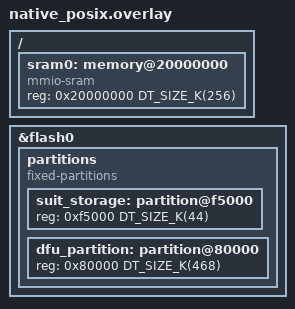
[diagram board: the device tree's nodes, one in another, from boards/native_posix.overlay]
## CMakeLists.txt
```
#
# Copyright (c) 2022 Nordic Semiconductor ASA
#
# SPDX-License-Identifier: LicenseRef-Nordic-5-Clause
#

cmake_minimum_required(VERSION 3.20.0)

find_package(Zephyr REQUIRED HINTS $ENV{ZEPHYR_BASE})

project(integration_test_envelope_decoder)
include(../cmake/test_template.cmake)

zephyr_library_link_libraries(suit_utils)
zephyr_library_link_libraries(suit_storage_interface)
zephyr_library_link_libraries(suit_execution_mode)
```

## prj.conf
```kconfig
#
# Copyright (c) 2022 Nordic Semiconductor ASA
#
# SPDX-License-Identifier: LicenseRef-Nordic-5-Clause
#

CONFIG_ZTEST=y

CONFIG_SUIT=y
CONFIG_SUIT_CRYPTO=y
CONFIG_SUIT_PROCESSOR=y
CONFIG_SUIT_PLATFORM=y
CONFIG_SUIT_LOG_LEVEL_DBG=y

CONFIG_SUIT_DEVCONFIG=y
CONFIG_SUIT_STORAGE=y
CONFIG_SUIT_MCI=y
CONFIG_SUIT_MCI_IMPL_CUSTOM=y
CONFIG_SUIT_METADATA=y
CONFIG_SUIT_PLAT_CHECK_COMPONENT_COMPATIBILITY=y
CONFIG_SUIT_PLAT_CHECK_CLASSES=y
CONFIG_SUIT_AUTHENTICATE=y

CONFIG_SUIT_CACHE=y
CONFIG_SUIT_DIGEST=y
CONFIG_SUIT_DIGEST_CACHE=y
CONFIG_SUIT_SINK_SELECTOR=y

CONFIG_SUIT_STREAM=y
CONFIG_SUIT_STREAM_SINK_DIGEST=y
CONFIG_SUIT_CHECK_IMAGE_MATCH=y

CONFIG_SUIT_STREAM_SINK_MEMPTR=y
CONFIG_SUIT_STREAM_SINK_FLASH=y
CONFIG_SUIT_STREAM_SOURCE_MEMPTR=y
CONFIG_SUIT_STREAM_SOURCE_CACHE=y

CONFIG_SUIT_UTILS=y
CONFIG_SUIT_MEMPTR_STORAGE=y

CONFIG_PSA_WANT_ALG_ECDSA=y

CONFIG_ZCBOR=y
CONFIG_ZCBOR_CANONICAL=y

CONFIG_FLASH=y
CONFIG_FLASH_MAP=y

CONFIG_SUIT_EXECUTION_MODE=y
```

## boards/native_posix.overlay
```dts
/*
 * Copyright (c) 2022 Nordic Semiconductor ASA
 *
 * SPDX-License-Identifier: LicenseRef-Nordic-5-Clause
 */

&flash0 {
	partitions {
		compatible = "fixed-partitions";
		#address-cells = <1>;
		#size-cells = <1>;

		/* Use the last 44KB of NVM as suit storage. */
		suit_storage: partition@f5000 {
			reg = <0xf5000 DT_SIZE_K(44)>;
		};

		/* Use the second half of NVM as DFU partition. */
		dfu_partition: partition@80000 {
			reg = <0x80000 DT_SIZE_K(468)>;
		};
	};
};

/ {
	sram0: memory@20000000 {
		compatible = "mmio-sram";
		reg = <0x20000000 DT_SIZE_K(256)>;
	};
};
```

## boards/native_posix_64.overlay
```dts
/*
 * Copyright (c) 2022 Nordic Semiconductor ASA
 *
 * SPDX-License-Identifier: LicenseRef-Nordic-5-Clause
 */

&flash0 {
	partitions {
		compatible = "fixed-partitions";
		#address-cells = <1>;
		#size-cells = <1>;

		/* Use the last 40KB of NVM as suit storage. */
		suit_storage: partition@f6000 {
			reg = <0xf6000 DT_SIZE_K(40)>;
		};

		/* Use the second half of NVM as DFU partition. */
		dfu_partition: partition@80000 {
			reg = <0x80000 DT_SIZE_K(472)>;
		};
	};
};

/ {
	sram0: memory@20000000 {
		compatible = "mmio-sram";
		reg = <0x20000000 DT_SIZE_K(256)>;
	};
};
```

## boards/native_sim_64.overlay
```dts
/*
 * Copyright (c) 2022 Nordic Semiconductor ASA
 *
 * SPDX-License-Identifier: LicenseRef-Nordic-5-Clause
 */

&flash0 {
	partitions {
		compatible = "fixed-partitions";
		#address-cells = <1>;
		#size-cells = <1>;

		/* Use the last 48KB of NVM as suit storage. */
		suit_storage: partition@f4000 {
			reg = <0xf4000 DT_SIZE_K(48)>;
		};

		/* Use the second half of NVM as DFU partition. */
		dfu_partition: partition@80000 {
			reg = <0x80000 DT_SIZE_K(468)>;
		};
	};
};

/ {
	sram0: memory@20000000 {
		compatible = "mmio-sram";
		reg = <0x20000000 DT_SIZE_K(256)>;
	};
};
```

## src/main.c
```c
/*
 * Copyright (c) 2022 Nordic Semiconductor ASA
 *
 * SPDX-License-Identifier: LicenseRef-Nordic-5-Clause
 */

#include <zephyr/ztest.h>
#include <stdint.h>
#include <zephyr/drivers/flash.h>
#include <zephyr/storage/flash_map.h>
#include <suit_plat_mem_util.h>

#include <suit.h>
#include <suit_platform.h>
#include <suit_mci.h>
#include <suit_storage.h>

#define DFU_PARTITION_ADDRESS (suit_plat_mem_nvm_ptr_get(DFU_PARTITION_OFFSET))
#define DFU_PARTITION_OFFSET  ((size_t)FIXED_PARTITION_OFFSET(dfu_partition))
#define DFU_PARTITION_SIZE    ((size_t)FIXED_PARTITION_SIZE(dfu_partition))

static void *test_suit_setup(void)
{
	int err = suit_storage_init();

	zassert_equal(err, 0, "Unable to initialize storage module");

	err = suit_mci_init();
	zassert_equal(err, 0, "Unable to initialize MCI module");

	err = suit_processor_init();
	zassert_equal(err, 0, "Unable to initialise SUIT processor (err: %d)", err);

	return NULL;
}

ZTEST_SUITE(envelope_decoder, NULL, test_suit_setup, NULL, NULL, NULL);

ZTEST(envelope_decoder, test_get_manifest_authenticated_metadata)
{
	int err = suit_processor_get_manifest_metadata(DFU_PARTITION_ADDRESS, DFU_PARTITION_SIZE,
						       false, NULL, NULL, NULL, NULL, NULL);

	zassert_equal(err, 0, "Reading authenticated envelope failed (err: %d)", err);
}

ZTEST(envelope_decoder, test_get_manifest_unauthenticated_metadata)
{
	int err = suit_processor_get_manifest_metadata(DFU_PARTITION_ADDRESS, DFU_PARTITION_SIZE,
						       true, NULL, NULL, NULL, NULL, NULL);

	zassert_equal(err, 0, "Reading unauthenticated envelope failed (err: %d)", err);
}

ZTEST(envelope_decoder, test_process_sequence_parse)
{
	int err = suit_process_sequence(DFU_PARTITION_ADDRESS, DFU_PARTITION_SIZE, SUIT_SEQ_PARSE);

	zassert_equal(err, 0, "Parsing SUIT envelope failed (err: %d)", err);
}
```
